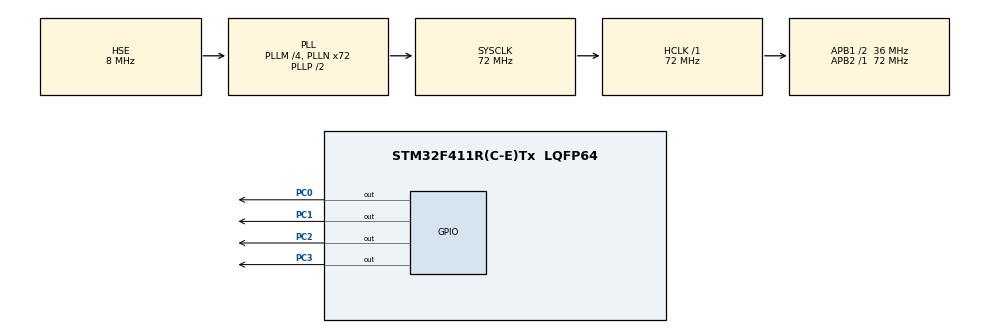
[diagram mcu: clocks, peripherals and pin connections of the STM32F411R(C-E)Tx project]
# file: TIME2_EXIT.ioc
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Mcu.Family=STM32F4
Mcu.Name=STM32F411R(C-E)Tx
Mcu.Package=LQFP64
NVIC.PriorityGroup=NVIC_PRIORITYGROUP_4
NVIC.TIM2_IRQn=true\:0\:0\:false\:false\:true\:true\:true
PC0.GPIO_PuPd=GPIO_PULLDOWN
PC0.GPIO_Speed=GPIO_SPEED_FREQ_HIGH
PC0.PinState=GPIO_PIN_SET
PC0.Signal=GPIO_Output
PC1.GPIO_PuPd=GPIO_PULLDOWN
PC1.GPIO_Speed=GPIO_SPEED_FREQ_HIGH
PC1.PinState=GPIO_PIN_SET
PC1.Signal=GPIO_Output
PC2.GPIO_ModeDefaultOutputPP=GPIO_MODE_OUTPUT_PP
PC2.GPIO_PuPd=GPIO_PULLDOWN
PC2.GPIO_Speed=GPIO_SPEED_FREQ_HIGH
PC2.PinState=GPIO_PIN_SET
PC2.Signal=GPIO_Output
PC3.GPIO_PuPd=GPIO_PULLDOWN
PC3.GPIO_Speed=GPIO_SPEED_FREQ_HIGH
PC3.PinState=GPIO_PIN_SET
PC3.Signal=GPIO_Output
PH0\ -\ OSC_IN.Mode=HSE-External-Oscillator
PH0\ -\ OSC_IN.Signal=RCC_OSC_IN
PH1\ -\ OSC_OUT.Mode=HSE-External-Oscillator
PH1\ -\ OSC_OUT.Signal=RCC_OSC_OUT
ProjectManager.HeapSize=0x200
ProjectManager.StackSize=0x400
ProjectManager.TargetToolchain=MDK-ARM V5
RCC.48MHZClocksFreq_Value=36000000
RCC.AHBFreq_Value=72000000
RCC.APB1CLKDivider=RCC_HCLK_DIV2
RCC.APB1Freq_Value=36000000
RCC.APB1TimFreq_Value=72000000
RCC.APB2Freq_Value=72000000
RCC.APB2TimFreq_Value=72000000
RCC.CortexFreq_Value=72000000
RCC.HCLKFreq_Value=72000000
RCC.HSE_VALUE=8000000
RCC.HSI_VALUE=16000000
RCC.LSE_VALUE=32768
RCC.PLLM=4
RCC.PLLN=72
RCC.PLLSourceVirtual=RCC_PLLSOURCE_HSE
RCC.SYSCLKFreq_VALUE=72000000
RCC.SYSCLKSource=RCC_SYSCLKSOURCE_PLLCLK
RCC.VCOOutputFreq_Value=144000000
TIM2.Period=4999
TIM2.Prescaler=7999
VP_TIM2_VS_ClockSourceINT.Mode=Internal
board=custom

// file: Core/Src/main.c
/* USER CODE BEGIN Header */
/**
  ******************************************************************************
  * @file           : main.c
  * @brief          : Main program body
  ******************************************************************************
  * @attention
  *
  * <h2><center>&copy; Copyright (c) 2023 STMicroelectronics.
  * All rights reserved.</center></h2>
  *
  * This software component is licensed by ST under BSD 3-Clause license,
  * the "License"; You may not use this file except in compliance with the
  * License. You may obtain a copy of the License at:
  *                        opensource.org/licenses/BSD-3-Clause
  *
  ******************************************************************************
  */
/* USER CODE END Header */
#include "main.h"

TIM_HandleTypeDef htim2;

void SystemClock_Config(void);
static void MX_GPIO_Init(void);
static void MX_TIM2_Init(void);

    //HAL_TIM_Base_Start_IT(&htim2);

int main(void)
{
  /* USER CODE BEGIN 1 */

  //HAL_TIM_Base_Start_IT(&htim2);
  /* USER CODE END 1 */

  /* MCU Configuration--------------------------------------------------------*/

  /* Reset of all peripherals, Initializes the Flash interface and the Systick. */
  HAL_Init();

  /* Configure the system clock */
  SystemClock_Config();

  /* Initialize all configured peripherals */
  MX_GPIO_Init();
  MX_TIM2_Init();
  /* USER CODE BEGIN 2 */
  HAL_TIM_Base_Start_IT(&htim2);
  /* USER CODE END 2 */

  /* Infinite loop */
  while (1)
  {

  }
}

void SystemClock_Config(void)
{
  RCC_OscInitTypeDef RCC_OscInitStruct = {0};
  RCC_ClkInitTypeDef RCC_ClkInitStruct = {0};

  /** Configure the main internal regulator output voltage
  */
  __HAL_RCC_PWR_CLK_ENABLE();
  __HAL_PWR_VOLTAGESCALING_CONFIG(PWR_REGULATOR_VOLTAGE_SCALE1);
  /** Initializes the RCC Oscillators according to the specified parameters
  * in the RCC_OscInitTypeDef structure.
  */
  RCC_OscInitStruct.OscillatorType = RCC_OSCILLATORTYPE_HSE;
  RCC_OscInitStruct.HSEState = RCC_HSE_ON;
  RCC_OscInitStruct.PLL.PLLState = RCC_PLL_ON;
  RCC_OscInitStruct.PLL.PLLSource = RCC_PLLSOURCE_HSE;
  RCC_OscInitStruct.PLL.PLLM = 4;
  RCC_OscInitStruct.PLL.PLLN = 72;
  RCC_OscInitStruct.PLL.PLLP = RCC_PLLP_DIV2;
  RCC_OscInitStruct.PLL.PLLQ = 4;
  if (HAL_RCC_OscConfig(&RCC_OscInitStruct) != HAL_OK)
  {
    Error_Handler();
  }
  /** Initializes the CPU, AHB and APB buses clocks
  */
  RCC_ClkInitStruct.ClockType = RCC_CLOCKTYPE_HCLK|RCC_CLOCKTYPE_SYSCLK
                              |RCC_CLOCKTYPE_PCLK1|RCC_CLOCKTYPE_PCLK2;
  RCC_ClkInitStruct.SYSCLKSource = RCC_SYSCLKSOURCE_PLLCLK;
  RCC_ClkInitStruct.AHBCLKDivider = RCC_SYSCLK_DIV1;
  RCC_ClkInitStruct.APB1CLKDivider = RCC_HCLK_DIV2;
  RCC_ClkInitStruct.APB2CLKDivider = RCC_HCLK_DIV1;

  if (HAL_RCC_ClockConfig(&RCC_ClkInitStruct, FLASH_LATENCY_2) != HAL_OK)
  {
    Error_Handler();
  }
}

static void MX_TIM2_Init(void)
{

  TIM_ClockConfigTypeDef sClockSourceConfig = {0};
  TIM_MasterConfigTypeDef sMasterConfig = {0};

  htim2.Instance = TIM2;
  htim2.Init.Prescaler = 7999;
  htim2.Init.CounterMode = TIM_COUNTERMODE_UP;
  htim2.Init.Period = 4999;
  htim2.Init.ClockDivision = TIM_CLOCKDIVISION_DIV1;
  htim2.Init.AutoReloadPreload = TIM_AUTORELOAD_PRELOAD_DISABLE;
  if (HAL_TIM_Base_Init(&htim2) != HAL_OK)
  {
    Error_Handler();
  }
  sClockSourceConfig.ClockSource = TIM_CLOCKSOURCE_INTERNAL;
  if (HAL_TIM_ConfigClockSource(&htim2, &sClockSourceConfig) != HAL_OK)
  {
    Error_Handler();
  }
  sMasterConfig.MasterOutputTrigger = TIM_TRGO_RESET;
  sMasterConfig.MasterSlaveMode = TIM_MASTERSLAVEMODE_DISABLE;
  if (HAL_TIMEx_MasterConfigSynchronization(&htim2, &sMasterConfig) != HAL_OK)
  {
    Error_Handler();
  }

}

static void MX_GPIO_Init(void)
{
  GPIO_InitTypeDef GPIO_InitStruct = {0};

  /* GPIO Ports Clock Enable */
  __HAL_RCC_GPIOH_CLK_ENABLE();
  __HAL_RCC_GPIOC_CLK_ENABLE();

  /*Configure GPIO pin Output Level */
  HAL_GPIO_WritePin(GPIOC, GPIO_PIN_0|GPIO_PIN_1|GPIO_PIN_2|GPIO_PIN_3, GPIO_PIN_SET);

  /*Configure GPIO pins : PC0 PC1 PC2 PC3 */
  GPIO_InitStruct.Pin = GPIO_PIN_0|GPIO_PIN_1|GPIO_PIN_2|GPIO_PIN_3;
  GPIO_InitStruct.Mode = GPIO_MODE_OUTPUT_PP;
  GPIO_InitStruct.Pull = GPIO_PULLDOWN;
  GPIO_InitStruct.Speed = GPIO_SPEED_FREQ_HIGH;
  HAL_GPIO_Init(GPIOC, &GPIO_InitStruct);

}

/* USER CODE BEGIN 4 */
void HAL_TIM_PeriodElapsedCallback(TIM_HandleTypeDef *htim)
{
    static unsigned char ledState = 0;
    if (htim == (&htim2))
    {
        if (ledState == 0)
            HAL_GPIO_WritePin(GPIOC,GPIO_PIN_0,GPIO_PIN_RESET);
        else
            HAL_GPIO_WritePin(GPIOC,GPIO_PIN_0,GPIO_PIN_SET);
        ledState = !ledState;
    }
}
/* USER CODE END 4 */

void Error_Handler(void)
{
  __disable_irq();
  while (1)
  {
  }
}

/************************ (C) COPYRIGHT STMicroelectronics *****END OF FILE****/
